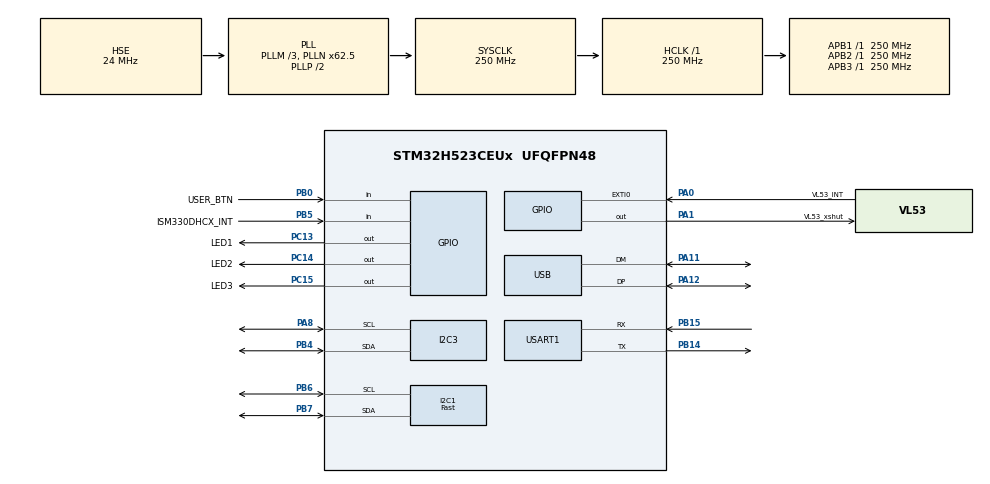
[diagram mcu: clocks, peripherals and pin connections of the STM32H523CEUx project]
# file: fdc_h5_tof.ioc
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BOOTPATH.BootPathName=LEGACY
BOOTPATH.UserSelectedBootPath=LEGACY
CORTEX_M33_NS.userName=CORTEX_M33
I2C1.I2C_Speed_Mode=I2C_Fast
I2C1.Timing=0x10C043E5
I2C3.Timing=0x60808CD3
Mcu.Family=STM32H5
Mcu.Name=STM32H523CEUx
Mcu.Package=UFQFPN48
NVIC.EXTI0_IRQn=true\:0\:0\:false\:false\:true\:true\:true\:true
NVIC.PriorityGroup=NVIC_PRIORITYGROUP_4
NVIC.TIM15_IRQn=true\:15\:0\:true\:false\:true\:false\:true\:true
NVIC.TIM2_IRQn=true\:0\:0\:false\:false\:true\:true\:true\:true
NVIC.TIM6_IRQn=true\:0\:0\:false\:false\:true\:true\:true\:true
NVIC.TimeBase=TIM15_IRQn
NVIC.TimeBaseIP=TIM15
NVIC.USART1_IRQn=true\:0\:0\:false\:false\:true\:true\:true\:true
NVIC.USB_DRD_FS_IRQn=true\:0\:0\:false\:false\:true\:true\:true\:true
PA0.GPIO_Label=VL53_INT
PA0.Signal=GPXTI0
PA1.GPIO_Label=VL53_xshut
PA1.Signal=GPIO_Output
PA11.Mode=Device
PA11.Signal=USB_DM
PA12.Mode=Device
PA12.Signal=USB_DP
PA13(JTMS/SWDIO).Mode=Serial_Wire
PA13(JTMS/SWDIO).Signal=DEBUG_JTMS-SWDIO
PA14(JTCK/SWCLK).Mode=Serial_Wire
PA14(JTCK/SWCLK).Signal=DEBUG_JTCK-SWCLK
PA8.Mode=I2C
PA8.Signal=I2C3_SCL
PB0.GPIO_Label=USER_BTN
PB0.Signal=GPIO_Input
PB14.Mode=Asynchronous
PB14.Signal=USART1_TX
PB15.Mode=Asynchronous
PB15.Signal=USART1_RX
PB4(NJTRST).Mode=I2C
PB4(NJTRST).Signal=I2C3_SDA
PB5.GPIO_Label=ISM330DHCX_INT
PB5.Signal=GPIO_Input
PB6.Mode=I2C
PB6.Signal=I2C1_SCL
PB7.Mode=I2C
PB7.Signal=I2C1_SDA
PC13.GPIO_Label=LED1
PC13.Signal=GPIO_Output
PC14-OSC32_IN(OSC32_IN).GPIO_Label=LED2
PC14-OSC32_IN(OSC32_IN).Signal=GPIO_Output
PC15-OSC32_OUT(OSC32_OUT).GPIO_Label=LED3
PC15-OSC32_OUT(OSC32_OUT).Signal=GPIO_Output
PH0-OSC_IN(PH0).Mode=HSE-External-Oscillator
PH0-OSC_IN(PH0).Signal=RCC_OSC_IN
PH1-OSC_OUT(PH1).Mode=HSE-External-Oscillator
PH1-OSC_OUT(PH1).Signal=RCC_OSC_OUT
ProjectManager.HeapSize=0x800
ProjectManager.StackSize=0x800
ProjectManager.TargetToolchain=CMake
RCC.ADCFreq_Value=250000000
RCC.AHBFreq_Value=250000000
RCC.APB1Freq_Value=250000000
RCC.APB1TimFreq_Value=250000000
RCC.APB2Freq_Value=250000000
RCC.APB2TimFreq_Value=250000000
RCC.APB3Freq_Value=250000000
RCC.CSI_VALUE=4000000
RCC.CortexFreq_Value=250000000
RCC.EPOD_VALUE=24000000
RCC.HCLKFreq_Value=250000000
RCC.HSE_VALUE=24000000
RCC.HSI48_VALUE=48000000
RCC.HSI_VALUE=64000000
RCC.LSE_VALUE=32768
RCC.LSIRC_VALUE=32000
RCC.PLL2FRACN=0
RCC.PLL3FRACN=0
RCC.PLLFRACN=4096
RCC.PLLM=3
RCC.PLLN=62
RCC.PLLSourceVirtual=RCC_PLL1_SOURCE_HSE
RCC.SYSCLKFreq_VALUE=250000000
RCC.SYSCLKSource=RCC_SYSCLKSOURCE_PLLCLK
RCC.USBFreq_Value=48000000
RCC.VCOOutputFreq_Value=500000000
STMicroelectronics.X-CUBE-AI.9.1.0.ActivationBufferSizeList=932
STMicroelectronics.X-CUBE-AI.9.1.0.ActivationBuffers=pool0
STMicroelectronics.X-CUBE-AI.9.1.0.ActivationNames=pool0
STMicroelectronics.X-CUBE-AI.9.1.0.ActivationSizes=AI_NETWORK_DATA_ACTIVATION_1_SIZE
STMicroelectronics.X-CUBE-AI.9.1.0.HeapSize=0x800
STMicroelectronics.X-CUBE-AI.9.1.0.InternalRamActivationBufferMaxSize=AI_NETWORK_DATA_ACTIVATIONS_SIZE
STMicroelectronics.X-CUBE-AI.9.1.0.LatestDirectoryUsed-dd74088e7566082c05417f942c240103cb2881e820c8bbd75c0e5f1a46940492=C\:\\Users\\binghui.lai\\ToF_CubeAI\\aztech_demo
STMicroelectronics.X-CUBE-AI.9.1.0.MaximumNumberOfInputLayer=1
STMicroelectronics.X-CUBE-AI.9.1.0.MaximumNumberOfOutputLayer=1
STMicroelectronics.X-CUBE-AI.9.1.0.MaximumSizeOfInputLayer=1
STMicroelectronics.X-CUBE-AI.9.1.0.MaximumSizeOfOutputLayer=1
STMicroelectronics.X-CUBE-AI.9.1.0.ModelActualCompression-dd74088e7566082c05417f942c240103cb2881e820c8bbd75c0e5f1a46940492=0.0
STMicroelectronics.X-CUBE-AI.9.1.0.ModelCompression-dd74088e7566082c05417f942c240103cb2881e820c8bbd75c0e5f1a46940492=None
STMicroelectronics.X-CUBE-AI.9.1.0.ModelFlashOccupation-dd74088e7566082c05417f942c240103cb2881e820c8bbd75c0e5f1a46940492=1196
STMicroelectronics.X-CUBE-AI.9.1.0.ModelHashList=dd74088e7566082c05417f942c240103cb2881e820c8bbd75c0e5f1a46940492
STMicroelectronics.X-CUBE-AI.9.1.0.ModelKind-dd74088e7566082c05417f942c240103cb2881e820c8bbd75c0e5f1a46940492=KERAS
STMicroelectronics.X-CUBE-AI.9.1.0.ModelMacc-dd74088e7566082c05417f942c240103cb2881e820c8bbd75c0e5f1a46940492=3440
STMicroelectronics.X-CUBE-AI.9.1.0.ModelName-dd74088e7566082c05417f942c240103cb2881e820c8bbd75c0e5f1a46940492=network
STMicroelectronics.X-CUBE-AI.9.1.0.ModelNameList=network
STMicroelectronics.X-CUBE-AI.9.1.0.ModelRamOccupation-dd74088e7566082c05417f942c240103cb2881e820c8bbd75c0e5f1a46940492=932
STMicroelectronics.X-CUBE-AI.9.1.0.ModelStructureFile-dd74088e7566082c05417f942c240103cb2881e820c8bbd75c0e5f1a46940492=C\:\\Users\\binghui.lai\\ToF_CubeAI\\aztech_demo\\ToF_model_time_series_people_demo.h5
STMicroelectronics.X-CUBE-AI.9.1.0.ModelType-dd74088e7566082c05417f942c240103cb2881e820c8bbd75c0e5f1a46940492=STM32Cube.AI MCU runtime
STMicroelectronics.X-CUBE-AI.9.1.0.ReadyForCodeGeneration=true
STMicroelectronics.X-CUBE-AI.9.1.0.StackSize=0x800
STMicroelectronics.X-CUBE-AI.9.1.0.WorkingBufferStartAddrList=0xFFFFFFFF
STMicroelectronics.X-CUBE-AI.9.1.0.XAaCUBEAaAICcArtificialOoIntelligenceJjCore=true
STMicroelectronics.X-CUBE-AI.9.1.0.copyWeightToRam-dd74088e7566082c05417f942c240103cb2881e820c8bbd75c0e5f1a46940492=false
STMicroelectronics.X-CUBE-AI.9.1.0.customLayerConfigEnabled-dd74088e7566082c05417f942c240103cb2881e820c8bbd75c0e5f1a46940492=false
STMicroelectronics.X-CUBE-AI.9.1.0.noOnnxIoTranspose-dd74088e7566082c05417f942c240103cb2881e820c8bbd75c0e5f1a46940492=false
STMicroelectronics.X-CUBE-AI.9.1.0.useInputAllocation-dd74088e7566082c05417f942c240103cb2881e820c8bbd75c0e5f1a46940492=true
STMicroelectronics.X-CUBE-AI.9.1.0.useOutputAllocation-dd74088e7566082c05417f942c240103cb2881e820c8bbd75c0e5f1a46940492=true
TIM2.PeriodNoDither=12499999
TIM6.PeriodNoDither=49999
TIM6.Prescaler=49
USART1.VirtualMode-Asynchronous=VM_ASYNC
USB.VirtualMode=Device_Only
VP_BOOTPATH_VS_BOOTPATH.Mode=BP_Activate
VP_CORTEX_M33_NS_VS_Hclk.Mode=Hclk_Mode
VP_DCACHE1_VS_DCACHE.Mode=DCACHE_Activate
VP_ICACHE_VS_ICACHE.Mode=DirectMappedCache
VP_MEMORYMAP_VS_MEMORYMAP.Mode=CurAppReg
VP_PWR_VS_DBSignals.Mode=DisableDeadBatterySignals
VP_PWR_VS_LPOM.Mode=PowerOptimisation
VP_PWR_VS_SECSignals.Mode=Security/Privilege
VP_STMicroelectronics.X-CUBE-AI_VS_ArtificialOoIntelligenceJjXAaCUBEAaAI_9.1.0.Mode=ArtificialOoIntelligenceJjXAaCUBEAaAI
VP_SYS_VS_tim15.Mode=TIM15
VP_TIM2_VS_ClockSourceINT.Mode=Internal
VP_TIM6_VS_ClockSourceINT.Mode=Enable_Timer
board=custom

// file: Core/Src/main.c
/* USER CODE BEGIN Header */
/**
  ******************************************************************************
  * @file           : main.c
  * @brief          : Main program body
  ******************************************************************************
  * @attention
  *
  * Copyright (c) 2026 STMicroelectronics.
  * All rights reserved.
  *
  * This software is licensed under terms that can be found in the LICENSE file
  * in the root directory of this software component.
  * If no LICENSE file comes with this software, it is provided AS-IS.
  *
  ******************************************************************************
  */
/* USER CODE END Header */
#include "main.h"
#include "dcache.h"
#include "i2c.h"
#include "icache.h"
#include "tim.h"
#include "usart.h"
#include "usb.h"
#include "gpio.h"

/* USER CODE BEGIN Includes */
#include "mpu.h"
#include "usb.h"
#include "app_main.h"
/* USER CODE END Includes */

void SystemClock_Config(void);

int main(void)
{

  /* MCU Configuration--------------------------------------------------------*/

  /* Reset of all peripherals, Initializes the Flash interface and the Systick. */
  HAL_Init();

  /* Configure the system clock */
  SystemClock_Config();

  /* USER CODE BEGIN SysInit */
  MPU_Config();
  /* USER CODE END SysInit */

  /* Initialize all configured peripherals */
  MX_GPIO_Init();
  MX_DCACHE1_Init();
  MX_I2C3_Init();
  MX_ICACHE_Init();
  MX_USART1_UART_Init();
  MX_I2C1_Init();
  MX_TIM2_Init();
  MX_TIM6_Init();
  /* USER CODE BEGIN 2 */
  MX_USB_PCD_Init();
  app_init();
  /* USER CODE END 2 */

  /* Infinite loop */
  /* USER CODE BEGIN WHILE */
  while (1)
  {
    app_main();
    /* USER CODE END WHILE */

  }
}

void SystemClock_Config(void)
{
  RCC_OscInitTypeDef RCC_OscInitStruct = {0};
  RCC_ClkInitTypeDef RCC_ClkInitStruct = {0};

  /** Configure the main internal regulator output voltage
  */
  __HAL_PWR_VOLTAGESCALING_CONFIG(PWR_REGULATOR_VOLTAGE_SCALE0);

  while(!__HAL_PWR_GET_FLAG(PWR_FLAG_VOSRDY)) {}

  /** Initializes the RCC Oscillators according to the specified parameters
  * in the RCC_OscInitTypeDef structure.
  */
  RCC_OscInitStruct.OscillatorType = RCC_OSCILLATORTYPE_HSI48|RCC_OSCILLATORTYPE_HSE;
  RCC_OscInitStruct.HSEState = RCC_HSE_ON;
  RCC_OscInitStruct.HSI48State = RCC_HSI48_ON;
  RCC_OscInitStruct.PLL.PLLState = RCC_PLL_ON;
  RCC_OscInitStruct.PLL.PLLSource = RCC_PLL1_SOURCE_HSE;
  RCC_OscInitStruct.PLL.PLLM = 3;
  RCC_OscInitStruct.PLL.PLLN = 62;
  RCC_OscInitStruct.PLL.PLLP = 2;
  RCC_OscInitStruct.PLL.PLLQ = 2;
  RCC_OscInitStruct.PLL.PLLR = 2;
  RCC_OscInitStruct.PLL.PLLRGE = RCC_PLL1_VCIRANGE_3;
  RCC_OscInitStruct.PLL.PLLVCOSEL = RCC_PLL1_VCORANGE_WIDE;
  RCC_OscInitStruct.PLL.PLLFRACN = 4096;
  if (HAL_RCC_OscConfig(&RCC_OscInitStruct) != HAL_OK)
  {
    Error_Handler();
  }

  /** Initializes the CPU, AHB and APB buses clocks
  */
  RCC_ClkInitStruct.ClockType = RCC_CLOCKTYPE_HCLK|RCC_CLOCKTYPE_SYSCLK
                              |RCC_CLOCKTYPE_PCLK1|RCC_CLOCKTYPE_PCLK2
                              |RCC_CLOCKTYPE_PCLK3;
  RCC_ClkInitStruct.SYSCLKSource = RCC_SYSCLKSOURCE_PLLCLK;
  RCC_ClkInitStruct.AHBCLKDivider = RCC_SYSCLK_DIV1;
  RCC_ClkInitStruct.APB1CLKDivider = RCC_HCLK_DIV1;
  RCC_ClkInitStruct.APB2CLKDivider = RCC_HCLK_DIV1;
  RCC_ClkInitStruct.APB3CLKDivider = RCC_HCLK_DIV1;

  if (HAL_RCC_ClockConfig(&RCC_ClkInitStruct, FLASH_LATENCY_5) != HAL_OK)
  {
    Error_Handler();
  }

  /** Configure the programming delay
  */
  __HAL_FLASH_SET_PROGRAM_DELAY(FLASH_PROGRAMMING_DELAY_2);
}

void HAL_TIM_PeriodElapsedCallback(TIM_HandleTypeDef *htim)
{
  if (htim->Instance == TIM15)
  {
    HAL_IncTick();
  }
}

void Error_Handler(void)
{
  __disable_irq();
  while (1)
  {
  }
}
